# nrf9230_enga_application register map
Vendor: Nordic Semiconductor; Series: nRF92; File version: 1
CPU: CM33 r0p4, little endian, MPU, FPU, 3 interrupt priority bits, 480 interrupts, 4 SAU regions
Registers are 32-bit, read-write, reset 0x0 unless marked. A register's access mark holds for its fields unless they carry their own. Offsets are from the block's base; [hi:lo] are bit positions; {n}, {i} and the like mark numbered series; 'fields as' and 'values as' point back to an identical list.

## CPUC_S — CM33 SubSystem
Base 0xE0080000
0x100 EVENTS_FPUIOC — An invalid operation exception has occurred in the FPU.
  [0] EVENTS_FPUIOC
    0=NotGenerated (Event not generated); 1=Generated (Event generated)
0x104 EVENTS_FPUDZC — A floating-point divide-by-zero exception has occurred in the FPU.
  [0] EVENTS_FPUDZC
    values as EVENTS_FPUIOC.EVENTS_FPUIOC
0x108 EVENTS_FPUOFC — A floating-point overflow exception has occurred in the FPU.
  [0] EVENTS_FPUOFC
    values as EVENTS_FPUIOC.EVENTS_FPUIOC
0x10C EVENTS_FPUUFC — A floating-point underflow exception has occurred in the FPU.
  [0] EVENTS_FPUUFC
    values as EVENTS_FPUIOC.EVENTS_FPUIOC
0x110 EVENTS_FPUIXC — A floating-point inexact exception has occurred in the FPU.
  [0] EVENTS_FPUIXC
    values as EVENTS_FPUIOC.EVENTS_FPUIOC
0x114 EVENTS_FPUIDC — A floating-point input denormal exception has occurred in the FPU.
  [0] EVENTS_FPUIDC
    values as EVENTS_FPUIOC.EVENTS_FPUIOC
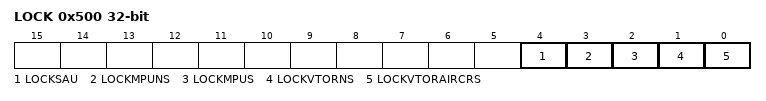
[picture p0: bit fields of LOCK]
0x500 LOCK — Register to lock the certain parts of the CPU from being modified.
  [4] LOCKSAU — Locks the Security Attribution Unit (SAU)
    0=NotLocked (SAU registers can be changed.); 1=Locked (Prevents changes to SAU registers.)
  [3] LOCKMPUNS — Locks the Memory Protection Unit (MPU) for non secure mode.
    0=NotLocked (MPU registers can be changed.); 1=Locked (Prevents changes to MPU registers.)
  [2] LOCKMPUS — Locks the Memory Protection Unit (MPU) for secure mode.
    values as LOCKMPUNS
  [1] LOCKVTORNS — Locks the Vector table Offset Register (VTOR) for non-secure mode.
    0=NotLocked (VTOR can be changed.); 1=Locked (Prevents changes to VTOR.)
  [0] LOCKVTORAIRCRS — Locks both the Vector table Offset Register (VTOR) and Application Interrupt and Reset Control Register (AIRCR) for secure mode.
    0=NotLocked (Both VTOR and AIRCR can be changed.); 1=Locked (Prevents changes to both VTOR and AIRCR.)
0x504 CPUID ro — The identifier for the CPU in this subsystem.
  [31:0] CPUID — The CPU identifier.

## RAMC_NS — RAM Controller 0
Base 0x42004000
Same registers: RAMC_S 0x52004000
0x500 WAITSTATES — Waitstates for read operations.
  [0] WAITSTATES — Number of waitstates for a read from the RAM.
0x600 SECBASE — Base address for secure access area.
  [31:0] ADDR — Base address
0x604 SECENABLE — Enable secure access restrictions.
  [0] ENABLE — Enable secure access restrictions
    0=Disable (Secure access restrictions disabled); 1=Enable (Secure access restrictions enabled)

## PCGCS000_S — PCGCSlave 0
Base 0x5200B000
Same registers: PCGCS010_S 0x5201B000
{0xC00+4i} PENALTY[{i}] (i=0..1) reset 0xFFFFFFFC — Description collection: Penalty level for power/clock pair n. When FULL_PCP_ZERO feature is not supported, PENALTY[0] address overlaps the PENALTY0 address and register description for PENALTY[0] is not valid.
  [1:0] PENALTY — Penalty level
0xC00 PENALTY0 (alternate view of PENALTY[*]) — Penalty level for power/clock pair 0. The register description is valid only when FULL_PCP_ZERO feature is not supported
  [1:0] PENALTY ro — Penalty level
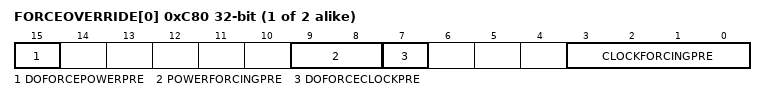
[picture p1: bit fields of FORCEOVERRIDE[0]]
{0xC80+4i} FORCEOVERRIDE[{i}] (i=0..1) — Description collection: Force override of power/clock pair n.
  [15] DOFORCEPOWERPRE, [9:8] POWERFORCINGPRE, [7] DOFORCECLOCKPRE, [3:0] CLOCKFORCINGPRE

## PCGCM000_S — PCGC Master 0
Base 0x5200F000
Same registers: PCGCM010_S 0x5201F000
{0xE0+4i} SETPWRCONTHRESHOLDBASE[{i}] (i=0..2) — Description collection: Set power consumption threshold base for power source / regulator n
  [3:0] SETPWRCONTHRESHOLDBASE
0xC00 UNLOCKBACKDOORS
  [15:0] UNLOCKBACKDOORS — Write: 0x00009375 to lock/unlock backdoors Read: 0x00000001 if backdoors is enabled Read: 0x00000000 if backdoors is disabled
0xC04 ENABLEPOWERREGFORCE
  [2:0] ENABLEPOWERREGFORCE
0xC08 POWERREGFORCE — Force reg
  [2:0] POWERREGFORCEREG
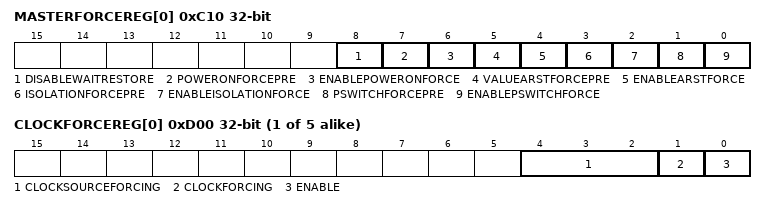
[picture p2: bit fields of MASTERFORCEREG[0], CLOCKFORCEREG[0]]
{0xC10+4i} MASTERFORCEREG[{i}] (i=0..0) — Description collection: Force reg
  [8] DISABLEWAITRESTORE — Turn off waiting for arst deactivation before retention restore
    1=Disable (Turn off waiting for arst deactivation before retention restore); 0=Enable (Wait for arst deactivation before retention restore)
  [7] POWERONFORCEPRE
  [6] ENABLEPOWERONFORCE
  [5] VALUEARSTFORCEPRE
  [4] ENABLEARSTFORCE
  [3] ISOLATIONFORCEPRE
  [2] ENABLEISOLATIONFORCE
  [1] PSWITCHFORCEPRE
  [0] ENABLEPSWITCHFORCE
{0xD00+4i} CLOCKFORCEREG[{i}] (i=0..4) — Description collection: Force clock n
  [4:2] CLOCKSOURCEFORCING
  [1] CLOCKFORCING
  [0] ENABLE — Enable clock forcing
